# AE402FA0E5597BE0_CM55_HP_View register map
Vendor: Alif Semiconductor; Series: E4; File version: 1.0
CPU: CM55 r1p0, selectable endian, MPU, FPU, double-precision FPU, DSP, VTOR, 8 interrupt priority bits, 1 SAU regions
Registers are 32-bit, read-write, reset 0x0 unless marked. A register's access mark holds for its fields unless they carry their own. Offsets are from the block's base; [hi:lo] are bit positions; {n}, {i} and the like mark numbered series.

## VBAT
Base 0x1A609000
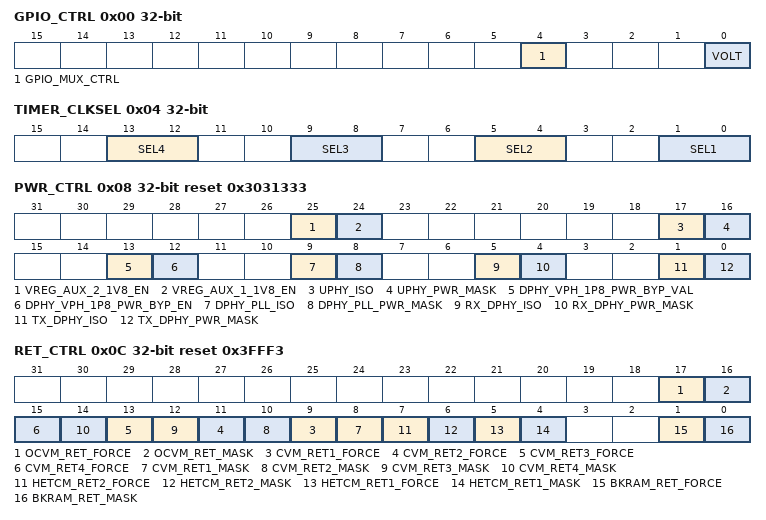
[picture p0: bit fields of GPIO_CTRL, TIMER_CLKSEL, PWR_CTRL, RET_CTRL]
0x00 GPIO_CTRL — GPIO 1.8 V / 3.3 V Power Control Register
  [4] GPIO_MUX_CTRL — Select which LPGPIO controller has access to the GPIOV_* pins
    0=LPGPIO controls the GPIOV_* pins; 1=LPGPIO_FAST controls the GPIOV_* pins
  [0] VOLT — Select voltage level for the 1.8-V/3.3-V (flex) I/O pins
    0=I/O pin will be used with a 3.3-V power; 1=I/O pin will be used with a 1.8-V power
0x04 TIMER_CLKSEL — LPTIMER Clock Select Register
  [13:12] SEL4 — LPTIMER3 clock select
    0=S32K_CLK; 1=128K_CLK (128 kHz); 2=External clock from LPTMR3_CLK_IO pin; 3=LPTIMER2 toggle output (LPTMR2_OUT)
  [9:8] SEL3 — LPTIMER2 clock select
    0=S32K_CLK; 1=128K_CLK (128 kHz); 2=External clock from LPTMR2_CLK_IO pin; 3=S32K_CLK
  [5:4] SEL2 — LPTIMER1 clock select
    0=S32K_CLK; 1=128K_CLK (128 kHz); 2=External clock from LPTMR1_CLK_IO pin; 3=LPTIMER0 toggle output (LPTMR0_OUT)
  [1:0] SEL1 — LPTIMER0 clock select
    0=S32K_CLK; 1=128K_CLK (128 kHz); 2=External clock from LPTMR0_CLK_IO pin; 3=S32K_CLK
0x08 PWR_CTRL reset 0x3031333 — Power Control Register
  [25] VREG_AUX_2_1V8_EN — Enable for AUX regulator 2
    0=Disable; 1=Enable
  [24] VREG_AUX_1_1V8_EN — Enable for AUX regulator 1
    0=Disable; 1=Enable
  [17] UPHY_ISO — Enable isolation for USB PHY
    0=Disable; 1=Enable
  [16] UPHY_PWR_MASK — Mask off the power for USB PHY
    0=Power not masked; 1=Power masked off
  [13] DPHY_VPH_1P8_PWR_BYP_VAL — Power setting for MIPI D-PHY 1.8 V supply. The setting is used only if DPHY_VPH_1P8_PWR_BYP_EN bit is enabled.
    0=Power disabled; 1=Power enabled
  [12] DPHY_VPH_1P8_PWR_BYP_EN — Power mode for MIPI D-PHY 1.8 V supply
    0=Power enabled whenever PD-6 is enabled; 1=Power specified by DPHY_VPH_1P8_PWR_BYP_VAL bit
  [9] DPHY_PLL_ISO — Enable isolation for MIPI PLL
    0=Disable; 1=Enable
  [8] DPHY_PLL_PWR_MASK — Mask off the power for MIPI PLL
    0=Power not masked; 1=Power masked off
  [5] RX_DPHY_ISO — Enable isolation for MIPI RX DPHY
    0=Disable; 1=Enable
  [4] RX_DPHY_PWR_MASK — Mask off the power for MIPI RX DPHY
    0=Power not masked; 1=Power masked off
  [1] TX_DPHY_ISO — Enable isolation for MIPI TX DPHY
    0=Disable; 1=Enable
  [0] TX_DPHY_PWR_MASK — Mask off the power for MIPI TX DPHY
    0=Power not masked; 1=Power masked off
0x0C RET_CTRL reset 0x3FFF3 — Memory Retention Control Register
  [17] OCVM_RET_FORCE — Memory retention force for SRAM1 RET
    0=Force enabling the memory retention; 1=No force
  [16] OCVM_RET_MASK — Memory retention force for SRAM1 RET
    0=No mask; 1=Disable the memory retention
  [2n+7] CVM_RET{n}_FORCE (n=1..4) — Memory retention force for SRAM0 RET{n}
    0=Force enabling the memory retention; 1=No force
  [2n+6] CVM_RET{n}_MASK (n=1..4) — Memory retention force for SRAM0 RET{n}
    0=No mask; 1=Disable the memory retention
  [7] HETCM_RET2_FORCE — Memory retention force for M55-HE TCM RET2
    0=Force enabling the memory retention; 1=No force
  [6] HETCM_RET2_MASK — Memory retention mask for M55-HE TCM RET2
    0=No mask; 1=Disable the memory retention
  [5] HETCM_RET1_FORCE — Memory retention force for M55-HE TCM RET1
    0=Force enabling the memory retention; 1=No force
  [4] HETCM_RET1_MASK — Memory retention mask for M55-HE TCM RET1
    0=No mask; 1=Disable the memory retention
  [1] BKRAM_RET_FORCE — Memory retention force for Utility SRAM
    0=Force enabling the memory retention; 1=No force
  [0] BKRAM_RET_MASK — Memory retention mask for Utility SRAM
    0=No mask; 1=Disable the memory retention
0x10 RTC_CLK_EN — LPRTC Clock Enable Register
  [0] CLK_EN — Enable SYST_PCLK and S32K_CLK for LPRTC. This bit must be set before any programming to LPRTC.
    0=Disable LPRTC clocks; 1=Enable LPRTC clocks
